# RA6M1 register map
Vendor: Renesas Electronics Corporation; Series: RA6; File version: 1.2
CPU: CM4 r0p1, little endian, MPU, FPU, VTOR, 4 interrupt priority bits
Registers are 8-bit, read-write, reset 0x0 unless marked. A register's access mark holds for its fields unless they carry their own. Offsets are from the block's base; [hi:lo] are bit positions; 'fields as' and 'values as' point back to an identical list.

## DMA — DMAC Module Activation
Base 0x40005200
0x00 DMAST — DMA Module Activation Register
  [0] DMST — DMAC Operation Enable
    0=DMAC activation is disabled; 1=DMAC activation is enabled

## DTC — Data Transfer Controller
Base 0x40005400
0x00 DTCCR reset 0x8 — DTC Control Register
  [4] RRS — DTC Transfer Information Read Skip Enable.
    0=Do not skip transfer information read; 1=Skip transfer information read when vector numbers match
0x04 DTCVBR 32-bit — DTC Vector Base Register
  [31:0] DTCVBR — DTC Vector Base Address.Note: A value cannot be set in the lower-order 10 bits. These bits are fixed to 0.
0x0C DTCST — DTC Module Start Register
  [0] DTCST — DTC Module Start
    0=DTC module stop; 1=DTC module start
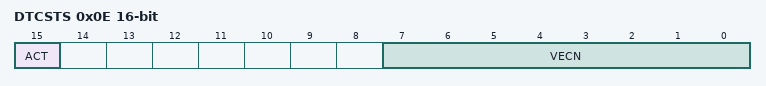
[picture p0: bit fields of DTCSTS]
0x0E DTCSTS 16-bit ro — DTC Status Register
  [15] ACT — DTC Active Flag
    0=DTC transfer operation is not in progress; 1=DTC transfer operation is in progress
  [7:0] VECN — DTC-Activating Vector Number MonitoringThese bits indicate the vector number for the activating source when DTC transfer is in progress.The value is only valid if DTC transfer is in progress (the value of the ACT flag is 1)

## MMF — Memory Mirror Function
Base 0x40001000
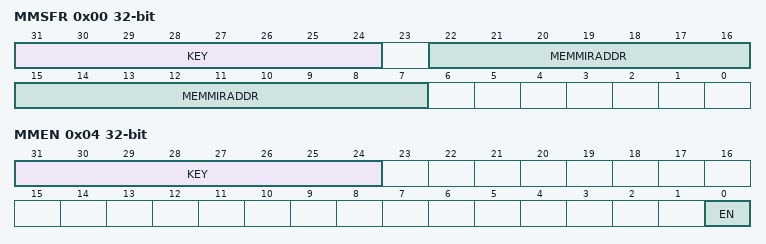
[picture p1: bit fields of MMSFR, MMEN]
0x00 MMSFR 32-bit — MemMirror Special Function Register
  [31:24] KEY wo — MMSFR Key Code
    219=Writing to the MEMMIRADDR bits are valid, when the KEY bits are written 0xDB; other=others (Writing to the MEMMIRADDR bits are invalid.)
  [22:7] MEMMIRADDR — Specifies the memory mirror address.NOTE: A value cannot be set in the low-order 7 bits. These bits are fixed to 0.
0x04 MMEN 32-bit — MemMirror Enable Register
  [31:24] KEY wo — MMEN Key Code
    219=Writing to the EN bit is valid, when the KEY bits are written 0xDB; other=others (Writing to the EN bit is invalid.)
  [0] EN — Memory Mirror Function Enable
    1=Memory Mirror Function is enabled; 0=Memory Mirror Function is disabled

## SRAM — SRAM Control
Base 0x40002000
0x00 PARIOAD — SRAM Parity Error Operation After Detection Register
  [0] OAD — Operation after Detection
    0=Non-maskable interrupt; 1=Reset
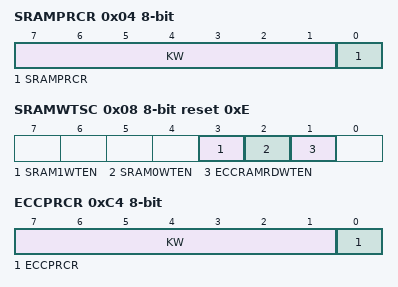
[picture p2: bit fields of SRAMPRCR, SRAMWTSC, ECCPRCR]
0x04 SRAMPRCR — SRAM Protection Register
  [7:1] KW wo — Write Key Code
    120=Writing to the RAMPRCR bit is valid, when the KEY bits are written 1111000b; other=others (Writing to the RAMPRCR bit is invalid.)
  [0] SRAMPRCR — Register Write Control
    0=Disable writes to protected registers; 1=Enable writes to protected registers
0x08 SRAMWTSC reset 0xE — RAM Wait State Control Register
  [3] SRAM1WTEN — SRAM1 Wait Enable
    0=Not add wait state in read access cycle to SRAM1; 1=Add wait state in read access cycle to SRAM1
  [2] SRAM0WTEN — SRAM0 Wait Enable
    0=Not add wait state in read access cycle to SRAM0; 1=Add wait state in read access cycle to SRAM0
  [1] ECCRAMRDWTEN — ECCRAM Read wait enable
    0=Not add wait state in read access cycle to SRAM0 (ECC area); 1=Add wait state in read access cycle to SRAM0 (ECC area)
0xC0 ECCMODE — ECCRAM Operating Mode Control Register
  [1:0] ECCMOD — ECC Operating Mode Select
    0=Disable ECC function; 1=Setting prohibited; 2=Enable ECC function without error checking; 3=Enable ECC function with error checking
0xC1 ECC2STS — ECCRAM 2-Bit Error Status Register
  [0] ECC2ERR write-0-clears read-modifies — ECC 2-Bit Error Status
    0=No 2-bit ECC error occurred; 1=2-bit ECC error occurred
0xC2 ECC1STSEN — ECCRAM 1-Bit Error Information Update Enable Register
  [0] E1STSEN — ECC 1-Bit Error Information Update Enable
    0=Disables updating of the 1-bit ECC error information; 1=Enables updating of the 1-bit ECC error information
0xC3 ECC1STS — ECCRAM 1-Bit Error Status Register
  [0] ECC1ERR write-0-clears read-modifies — ECC 1-Bit Error Status
    0=No 1-bit ECC error occurred; 1=1-bit ECC error occurred
0xC4 ECCPRCR — ECCRAM Protection Register
  [7:1] KW wo — Write Key Code
    120=Writing to the ECCRAMPRCR bit is valid, when the KEY bits are written 1111000b; other=others (Writing to the ECCRAMPRCR bit is invalid.)
  [0] ECCPRCR — ECCRAMETST Register Write Control
    values as SRAMPRCR.SRAMPRCR
0xD4 ECCETST — ECC Test Control Register
  [0] TSTBYP — ECC Bypass Select
    0=ECC bypass disabled; 1=ECC bypass enabled
0xD8 ECCOAD — RAM ECC Error Operation After Detection Register
  [0] OAD — Operation after Detection
    0=Non maskable interrupt; 1=Internal reset
